AUTOSAR XML (schema 4-2-2)
package /ComponentTypes
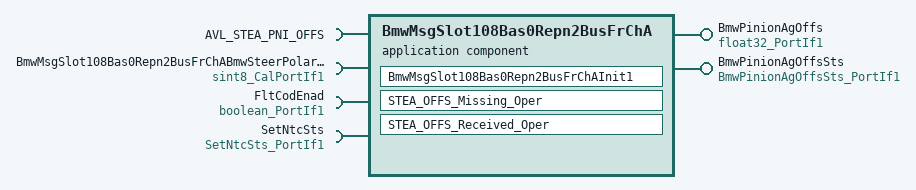
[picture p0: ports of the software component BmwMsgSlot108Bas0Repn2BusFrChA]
  application sw component type BmwMsgSlot108Bas0Repn2BusFrChA
    provide port BmwPinionAgOffs: nonqueued-sender-com-spec{data-element=Val, init-value=0}, provided-interface=float32_PortIf1
    provide port BmwPinionAgOffsSts: nonqueued-sender-com-spec{data-element=Val, init-value=4}, provided-interface=BmwPinionAgOffsSts_PortIf1
    4 x require port:
      AVL_STEA_PNI_OFFS: nonqueued-receiver-com-spec{data-element=AVL_STEA_PNI_OFFS, uses-end-to-end-protection=true, alive-timeout=0.11, enable-update=true, filter=data-filter-type=ALWAYS, init-value=2046}, required-interface=AVL_STEA_PNI_OFFS
      BmwMsgSlot108Bas0Repn2BusFrChABmwSteerPolarity: parameter-require-com-spec{init-value=-1, parameter=Val}, required-interface=sint8_CalPortIf1
      FltCodEnad: nonqueued-receiver-com-spec{data-element=Logl, filter=data-filter-type=ALWAYS, init-value=1}, required-interface=boolean_PortIf1
      SetNtcSts: client-com-spec=Oper, required-interface=SetNtcSts_PortIf1
    behavior BmwMsgSlot108Bas0Repn2BusFrChA_InternalBehavior
      ar-typed-per-instance-memorys:
        5 x data, all with sw-calibration-access=READ-ONLY:
          AvlSteaPniOffsFaildCnt: type=uint8
          AvlSteaPniOffsPassdCnt: type=uint8
          BmwPinionAgOffsPrev: type=float32
          MissingMsgCnt: type=uint8
          RxMsgCnt: type=uint8
      init event BmwMsgSlot108Bas0Repn2BusFrChA_InitEvent: start-on-event=BmwMsgSlot108Bas0Repn2BusFrChAInit1
      data receive error event DRET_STEA_OFFS_Missing_Oper_AVL_STEA_PNI_OFFS_AVL_STEA_PNI_OFFS: start-on-event=STEA_OFFS_Missing_Oper, data=AVL_STEA_PNI_OFFS.AVL_STEA_PNI_OFFS
      data received event DRT_STEA_OFFS_Received_Oper_AVL_STEA_PNI_OFFS_AVL_STEA_PNI_OFFS: start-on-event=STEA_OFFS_Received_Oper, data=AVL_STEA_PNI_OFFS.AVL_STEA_PNI_OFFS
      port-api-options:
        enable-take-address=false, error-handling=NO-TRANSFORMER-ERROR-HANDLING, indirect-api=false, port=AVL_STEA_PNI_OFFS
        enable-take-address=false, error-handling=NO-TRANSFORMER-ERROR-HANDLING, indirect-api=false, port=BmwMsgSlot108Bas0Repn2BusFrChABmwSteerPolarity
        enable-take-address=false, error-handling=NO-TRANSFORMER-ERROR-HANDLING, indirect-api=false, port=BmwPinionAgOffs
        enable-take-address=false, error-handling=NO-TRANSFORMER-ERROR-HANDLING, indirect-api=false, port=BmwPinionAgOffsSts
        enable-take-address=false, error-handling=NO-TRANSFORMER-ERROR-HANDLING, indirect-api=false, port=FltCodEnad
        enable-take-address=false, error-handling=NO-TRANSFORMER-ERROR-HANDLING, indirect-api=false, port=SetNtcSts
      runnable BmwMsgSlot108Bas0Repn2BusFrChAInit1
        sync call SC_SetNtcSts_Oper: operation=SetNtcSts.Oper, timeout=0
      runnable STEA_OFFS_Missing_Oper
        data-receive-point-by-arguments:
          access REC_FltCodEnad_Logl: accessed-variable=FltCodEnad.Logl
        data-send-points:
          access SEND_BmwPinionAgOffs_Val: accessed-variable=BmwPinionAgOffs.Val
          access SEND_BmwPinionAgOffsSts_Val: accessed-variable=BmwPinionAgOffsSts.Val
        sync call SC_SetNtcSts_Oper: operation=SetNtcSts.Oper, timeout=0
      runnable STEA_OFFS_Received_Oper
        data-receive-point-by-arguments:
          access REC_AVL_STEA_PNI_OFFS_AVL_STEA_PNI_OFFS: accessed-variable=AVL_STEA_PNI_OFFS.AVL_STEA_PNI_OFFS
          access REC_FltCodEnad_Logl: accessed-variable=FltCodEnad.Logl
        data-send-points:
          access SEND_BmwPinionAgOffs_Val: accessed-variable=BmwPinionAgOffs.Val
          access SEND_BmwPinionAgOffsSts_Val: accessed-variable=BmwPinionAgOffsSts.Val
        sync call SC_SetNtcSts_Oper: operation=SetNtcSts.Oper, timeout=0
  swc implementation BmwMsgSlot108Bas0Repn2BusFrChA_Implementation: behavior=BmwMsgSlot108Bas0Repn2BusFrChA_InternalBehavior
    code-descriptors:
      code Default: artifact-descriptors=autosar-engineering-object={short-label=Default, category=SWSRC}
